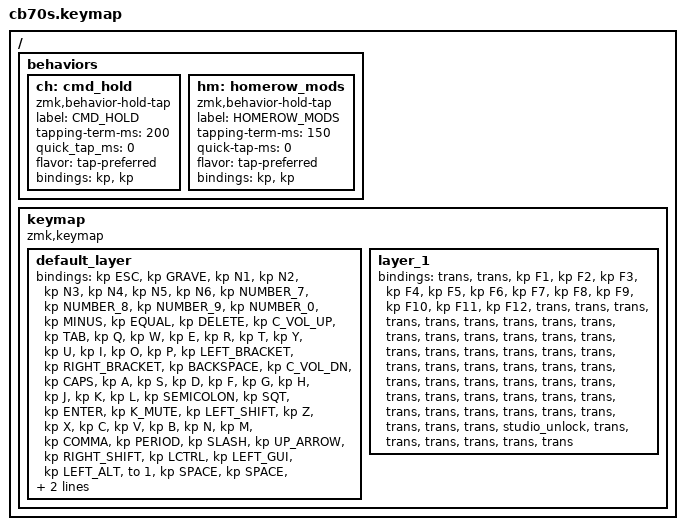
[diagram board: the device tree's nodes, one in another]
#include <behaviors.dtsi>
#include <dt-bindings/zmk/keys.h>

#define DEFAULT 0

#define CMDR(usage) &ch LG(usage) usage
#define OPTR(usage) &ch LA(usage) usage

/ {
    behaviors {
        ch: cmd_hold {
            compatible = "zmk,behavior-hold-tap";
            label = "CMD_HOLD";
            #binding-cells = <2>;
            tapping-term-ms = <200>;
            quick_tap_ms = <0>;
            flavor = "tap-preferred";
            bindings = <&kp>, <&kp>;
        };

        hm: homerow_mods {
            compatible = "zmk,behavior-hold-tap";
            label = "HOMEROW_MODS";
            #binding-cells = <2>;
            tapping-term-ms = <150>;
            quick-tap-ms = <0>;
            flavor = "tap-preferred";
            bindings = <&kp>, <&kp>;
        };
    };

    keymap {
        compatible = "zmk,keymap";

        default_layer {
            bindings = <
&kp ESC  &kp GRAVE  &kp N1  &kp N2  &kp N3  &kp N4  &kp N5  &kp N6    &kp NUMBER_7  &kp NUMBER_8  &kp NUMBER_9  &kp NUMBER_0  &kp MINUS  &kp EQUAL  &kp DELETE  &kp C_VOL_UP  &kp TAB  &kp Q  &kp W  &kp E  &kp R  &kp T  &kp Y  &kp U  &kp I  &kp O  &kp P  &kp LEFT_BRACKET  &kp RIGHT_BRACKET  &kp BACKSPACE  &kp C_VOL_DN  &kp CAPS  &kp A  &kp S  &kp D  &kp F  &kp G  &kp H  &kp J  &kp K  &kp L  &kp SEMICOLON  &kp SQT  &kp ENTER  &kp K_MUTE  &kp LEFT_SHIFT  &kp Z  &kp X  &kp C  &kp V  &kp B  &kp N  &kp M  &kp COMMA  &kp PERIOD  &kp SLASH  &kp UP_ARROW  &kp RIGHT_SHIFT  &kp LCTRL  &kp LEFT_GUI  &kp LEFT_ALT  &to 1  &kp SPACE  &kp SPACE  &kp RCTRL  &kp RIGHT_ALT  &kp LEFT_ARROW  &kp DOWN_ARROW  &kp RIGHT_ARROW
            >;
        };

        layer_1 {
            bindings = <
&trans  &trans  &kp F1  &kp F2  &kp F3  &kp F4  &kp F5  &kp F6    &kp F7  &kp F8  &kp F9  &kp F10  &kp F11  &kp F12  &trans  &trans  &trans  &trans  &trans  &trans  &trans  &trans  &trans  &trans  &trans  &trans  &trans  &trans  &trans  &trans  &trans  &trans  &trans  &trans  &trans  &trans  &trans  &trans  &trans  &trans  &trans  &trans  &trans  &trans  &trans  &trans  &trans  &trans  &trans  &trans  &trans  &trans  &trans  &trans  &trans  &trans  &trans  &trans  &trans  &trans  &trans  &trans  &studio_unlock  &trans  &trans  &trans  &trans  &trans  &trans
            >;
        };
    };
};




